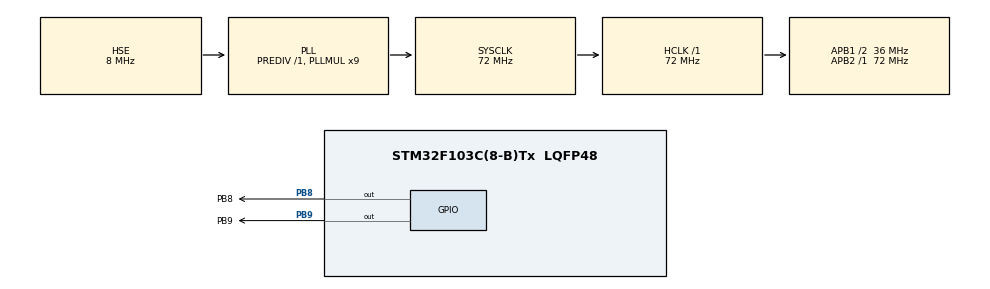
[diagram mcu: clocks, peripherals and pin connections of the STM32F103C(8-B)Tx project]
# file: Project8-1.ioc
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Dma.MEMTOMEM.0.Direction=DMA_MEMORY_TO_MEMORY
Dma.MEMTOMEM.0.Instance=DMA1_Channel1
Dma.MEMTOMEM.0.MemDataAlignment=DMA_MDATAALIGN_BYTE
Dma.MEMTOMEM.0.MemInc=DMA_MINC_ENABLE
Dma.MEMTOMEM.0.Mode=DMA_NORMAL
Dma.MEMTOMEM.0.PeriphDataAlignment=DMA_PDATAALIGN_BYTE
Dma.MEMTOMEM.0.PeriphInc=DMA_PINC_ENABLE
Dma.MEMTOMEM.0.Priority=DMA_PRIORITY_LOW
Dma.Request0=MEMTOMEM
Mcu.Family=STM32F1
Mcu.Name=STM32F103C(8-B)Tx
Mcu.Package=LQFP48
NVIC.PriorityGroup=NVIC_PRIORITYGROUP_4
PA13.Mode=Serial_Wire
PA13.Signal=SYS_JTMS-SWDIO
PA14.Mode=Serial_Wire
PA14.Signal=SYS_JTCK-SWCLK
PB8.GPIO_Label=PB8
PB8.Signal=GPIO_Output
PB9.GPIO_Label=PB9
PB9.Signal=GPIO_Output
PC14-OSC32_IN.Mode=LSE-External-Oscillator
PC14-OSC32_IN.Signal=RCC_OSC32_IN
PC15-OSC32_OUT.Mode=LSE-External-Oscillator
PC15-OSC32_OUT.Signal=RCC_OSC32_OUT
PD0-OSC_IN.Mode=HSE-External-Oscillator
PD0-OSC_IN.Signal=RCC_OSC_IN
PD1-OSC_OUT.Mode=HSE-External-Oscillator
PD1-OSC_OUT.Signal=RCC_OSC_OUT
ProjectManager.HeapSize=0x200
ProjectManager.StackSize=0x400
ProjectManager.TargetToolchain=MDK-ARM V5.32
RCC.AHBFreq_Value=72000000
RCC.APB1CLKDivider=RCC_HCLK_DIV2
RCC.APB1Freq_Value=36000000
RCC.APB1TimFreq_Value=72000000
RCC.APB2Freq_Value=72000000
RCC.APB2TimFreq_Value=72000000
RCC.HCLKFreq_Value=72000000
RCC.PLLMUL=RCC_PLL_MUL9
RCC.PLLSourceVirtual=RCC_PLLSOURCE_HSE
RCC.SYSCLKFreq_VALUE=72000000
RCC.SYSCLKSource=RCC_SYSCLKSOURCE_PLLCLK
RCC.USBFreq_Value=72000000
board=custom

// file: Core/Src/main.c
/* USER CODE BEGIN Header */
/**
  ******************************************************************************
  * @file           : main.c
  * @brief          : Main program body
  ******************************************************************************
  * @attention
  *
  * Copyright (c) 2025 STMicroelectronics.
  * All rights reserved.
  *
  * This software is licensed under terms that can be found in the LICENSE file
  * in the root directory of this software component.
  * If no LICENSE file comes with this software, it is provided AS-IS.
  *
  ******************************************************************************
  */
/* USER CODE END Header */
#include "main.h"
#include "dma.h"
#include "gpio.h"

/* USER CODE BEGIN Includes */
#include "OLED.h"
/* USER CODE END Includes */

/* USER CODE BEGIN PV */
uint8_t DataA[] = {0x01,0x02,0x03,0x04};//定义测试数组DataA，为数据源
uint8_t DataB[] = {0, 0, 0, 0};		  //定义测试数组DataB，为数据目的地
/* USER CODE END PV */

void SystemClock_Config(void);

int main(void)
{

  /* MCU Configuration--------------------------------------------------------*/

  /* Reset of all peripherals, Initializes the Flash interface and the Systick. */
  HAL_Init();

  /* Configure the system clock */
  SystemClock_Config();

  /* Initialize all configured peripherals */
  MX_GPIO_Init();
  MX_DMA_Init();
  /* USER CODE BEGIN 2 */
  // 现在cubemx中配置OLED相关引脚和开启DMA1 CHANNEL1
  // 按照之前的程序中的步骤添加和配置OLED相关文件
  // 模块初始化
  OLED_Init();      // OLED初始化
  OLED_Clear();
  OLED_ShowString(1,1,"DataA:");// 显示静态名称
  OLED_ShowHexNum(1, 8, (uint32_t)DataA, 8);// 显示数组的首地址
  OLED_ShowString(3,1,"DataB:");// 显示静态名称
  OLED_ShowHexNum(3, 8, (uint32_t)DataB, 8);// 显示数组的首地址
  /* USER CODE END 2 */

  /* Infinite loop */
  /* USER CODE BEGIN WHILE */
  while (1)
  {
	  DataA[0] ++;		//变换测试数据
	  DataA[1] ++;
	  DataA[2] ++;
	  DataA[3] ++;
	  OLED_ShowHexNum(2, 1, DataA[0], 2);		//显示数组DataA
	  OLED_ShowHexNum(2, 4, DataA[1], 2);
	  OLED_ShowHexNum(2, 7, DataA[2], 2);
	  OLED_ShowHexNum(2, 10, DataA[3], 2);
	  OLED_ShowHexNum(4, 1, DataB[0], 2);		//显示数组DataB
	  OLED_ShowHexNum(4, 4, DataB[1], 2);
	  OLED_ShowHexNum(4, 7, DataB[2], 2);
	  OLED_ShowHexNum(4, 10, DataB[3], 2);
	  HAL_Delay(1000); //延时1s，观察转运前的现象

	  // 启动DMA
	  HAL_DMA_Start(&hdma_memtomem_dma1_channel1,(uint32_t)DataA,(uint32_t)DataB,4);
	  // 等待传输完成
	  HAL_DMA_PollForTransfer(&hdma_memtomem_dma1_channel1,HAL_DMA_FULL_TRANSFER,HAL_MAX_DELAY);

	  OLED_ShowHexNum(2, 1, DataA[0], 2);		//显示数组DataA
	  OLED_ShowHexNum(2, 4, DataA[1], 2);
	  OLED_ShowHexNum(2, 7, DataA[2], 2);
	  OLED_ShowHexNum(2, 10, DataA[3], 2);
	  OLED_ShowHexNum(4, 1, DataB[0], 2);		//显示数组DataB
	  OLED_ShowHexNum(4, 4, DataB[1], 2);
      OLED_ShowHexNum(4, 7, DataB[2], 2);
	  OLED_ShowHexNum(4, 10, DataB[3], 2);

	  HAL_Delay(1000);//延时1s，观察转运后的现象
    /* USER CODE END WHILE */

  }
}

void SystemClock_Config(void)
{
  RCC_OscInitTypeDef RCC_OscInitStruct = {0};
  RCC_ClkInitTypeDef RCC_ClkInitStruct = {0};

  /** Initializes the RCC Oscillators according to the specified parameters
  * in the RCC_OscInitTypeDef structure.
  */
  RCC_OscInitStruct.OscillatorType = RCC_OSCILLATORTYPE_HSE;
  RCC_OscInitStruct.HSEState = RCC_HSE_ON;
  RCC_OscInitStruct.HSEPredivValue = RCC_HSE_PREDIV_DIV1;
  RCC_OscInitStruct.HSIState = RCC_HSI_ON;
  RCC_OscInitStruct.PLL.PLLState = RCC_PLL_ON;
  RCC_OscInitStruct.PLL.PLLSource = RCC_PLLSOURCE_HSE;
  RCC_OscInitStruct.PLL.PLLMUL = RCC_PLL_MUL9;
  if (HAL_RCC_OscConfig(&RCC_OscInitStruct) != HAL_OK)
  {
    Error_Handler();
  }

  /** Initializes the CPU, AHB and APB buses clocks
  */
  RCC_ClkInitStruct.ClockType = RCC_CLOCKTYPE_HCLK|RCC_CLOCKTYPE_SYSCLK
                              |RCC_CLOCKTYPE_PCLK1|RCC_CLOCKTYPE_PCLK2;
  RCC_ClkInitStruct.SYSCLKSource = RCC_SYSCLKSOURCE_PLLCLK;
  RCC_ClkInitStruct.AHBCLKDivider = RCC_SYSCLK_DIV1;
  RCC_ClkInitStruct.APB1CLKDivider = RCC_HCLK_DIV2;
  RCC_ClkInitStruct.APB2CLKDivider = RCC_HCLK_DIV1;

  if (HAL_RCC_ClockConfig(&RCC_ClkInitStruct, FLASH_LATENCY_2) != HAL_OK)
  {
    Error_Handler();
  }
}

void Error_Handler(void)
{
  __disable_irq();
  while (1)
  {
  }
}
